# PY32F030xx register map
Vendor: Puya; Series: PY32F0; File version: 1.0.0
CPU: CM0+ r0p1, little endian, no MPU, no FPU, 4 interrupt priority bits
Registers are 32-bit, read-write, reset 0x0 unless marked. A register's access mark holds for its fields unless they carry their own. Offsets are from the block's base; [hi:lo] are bit positions; {n}, {i} and the like mark numbered series; 'fields as' and 'values as' point back to an identical list.

## CRC — CRC calculation unit
Base 0x40023000
0x00 DR reset 0xFFFFFFFF — Data register
  [31:0] DR — Data Register
0x04 IDR — Independent Data register
  [7:0] IDR
0x08 CR wo — Control register
  [0] RESET — Reset bit
    1=Resets the CRC calculation unit and sets the data register to 0xFFFF FFFF

## LED — LED CONTROLLER
Base 0x40002400
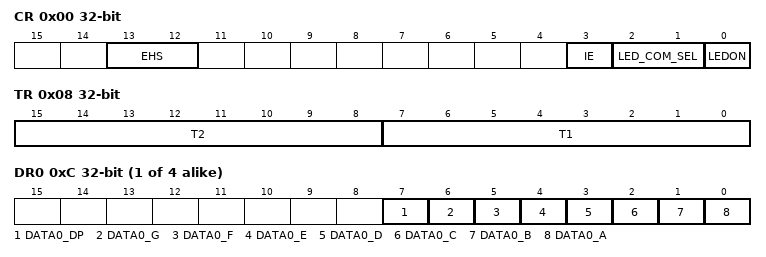
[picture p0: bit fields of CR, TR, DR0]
0x00 CR — Control register
  [13:12] EHS — Light control
    0=NoComOutput; 1=HighSink (LED COM output high sink, driven level configured by GPIO_OSPEEDR)
  [3] IE — LED interrupt enable
    0=Disabled (Disable interrupt); 1=Enabled (Enable interrupt)
  [2:1] LED_COM_SEL — LED COM Selection
    0=OneDigit; 1=Two digits sequentially; 2=Three digits sequentially; 3=Four digits sequentially
  [0] LEDON — LED enable
    0=Disabled (Disable LED controller); 1=Enabled (Enable LED controller)
0x04 PR — Prescaler register
  [7:0] PR — Prescaler control
0x08 TR — Time register
  [15:8] T2 — Switch time
  [7:0] T1 — Light on time
{0xC+4i} DR{i} (i=0..3) — Data{i} register
  [7] DATA{i}_DP — 8-bit data register
    0=Off (DATAx seg DP off); 1=On (DATAx seg DP on)
  [6] DATA{i}_G — 8-bit data register
    0=Off (DATAx seg G off); 1=On (DATAx seg G on)
  [5] DATA{i}_F — 8-bit data register
    0=Off (DATAx seg F off); 1=On (DATAx seg F on)
  [4] DATA{i}_E — 8-bit data register
    0=Off (DATAx seg E off); 1=On (DATAx seg E on)
  [3] DATA{i}_D — 8-bit data register
    0=Off (DATAx seg D off); 1=On (DATAx seg D on)
  [2] DATA{i}_C — 8-bit data register
    0=Off (DATAx seg C off); 1=On (DATAx seg C on)
  [1] DATA{i}_B — 8-bit data register
    0=Off (DATAx seg B off); 1=On (DATAx seg B on)
  [0] DATA{i}_A — 8-bit data register
    0=Off (DATAx seg A off); 1=On (DATAx seg A on)
0x1C IR — Interrupt register 1
  [0] FLAG — interrupt flag
    on read: 0=Not complete one digit lit; 1=Completed (Complete one digit lit) | on write: 1=Clear interrupt flag

## DBG — Debug support
Base 0x40015800
0x00 IDCODE ro — MCU Device ID Code Register
  [31:0] CODE — DBG ID code register
0x04 CR — Debug MCU Configuration Register
  [1] DBG_STOP — Debug Stop Mode
    0=Disabled (Debug Stop Mode Disabled); 1=Enabled (Debug Stop Mode Enabled)
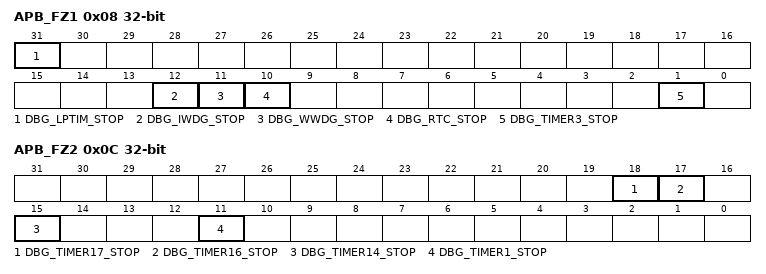
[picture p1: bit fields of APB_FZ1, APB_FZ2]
0x08 APB_FZ1 — APB Freeze Register1
  [31] DBG_LPTIM_STOP — Debug LPTIM stopped when Core is halted
    0=Continue (LPTIMx counter clock is fed even if the core is halted); 1=Stop (LPTIMx counter clock is stopped when the core is halted)
  [12] DBG_IWDG_STOP — Debug Independent Wachdog stopped when Core is halted
    0=Continue (The independent watchdog counter clock continues even if the core is halted); 1=Stop (The independent watchdog counter clock is stopped when the core is halted)
  [11] DBG_WWDG_STOP — Debug Window Wachdog stopped when Core is halted
    0=Continue (The window watchdog counter clock continues even if the core is halted); 1=Stop (The window watchdog counter clock is stopped when the core is halted)
  [10] DBG_RTC_STOP — Debug RTC stopped when Core is halted
    0=Continue (The clock of the RTC counter is fed even if the core is halted); 1=Stop (The clock of the RTC counter is stopped when the core is halted)
  [1] DBG_TIMER3_STOP — Debug Timer 3 stopped when Core is halted
    0=Continue (The counter clock of TIMx is fed even if the core is halted); 1=Stop (The counter clock of TIMx is stopped when the core is halted)
0x0C APB_FZ2 — APB Freeze Register2
  [all] fields
    values as APB_FZ1.DBG_TIMER3_STOP
  [18] DBG_TIMER17_STOP — Debug Timer 17 stopped when Core is halted
  [17] DBG_TIMER16_STOP — Debug Timer 16 stopped when Core is halted
  [15] DBG_TIMER14_STOP — Debug Timer 14 stopped when Core is halted
  [11] DBG_TIMER1_STOP — Debug Timer 1 stopped when Core is halted
